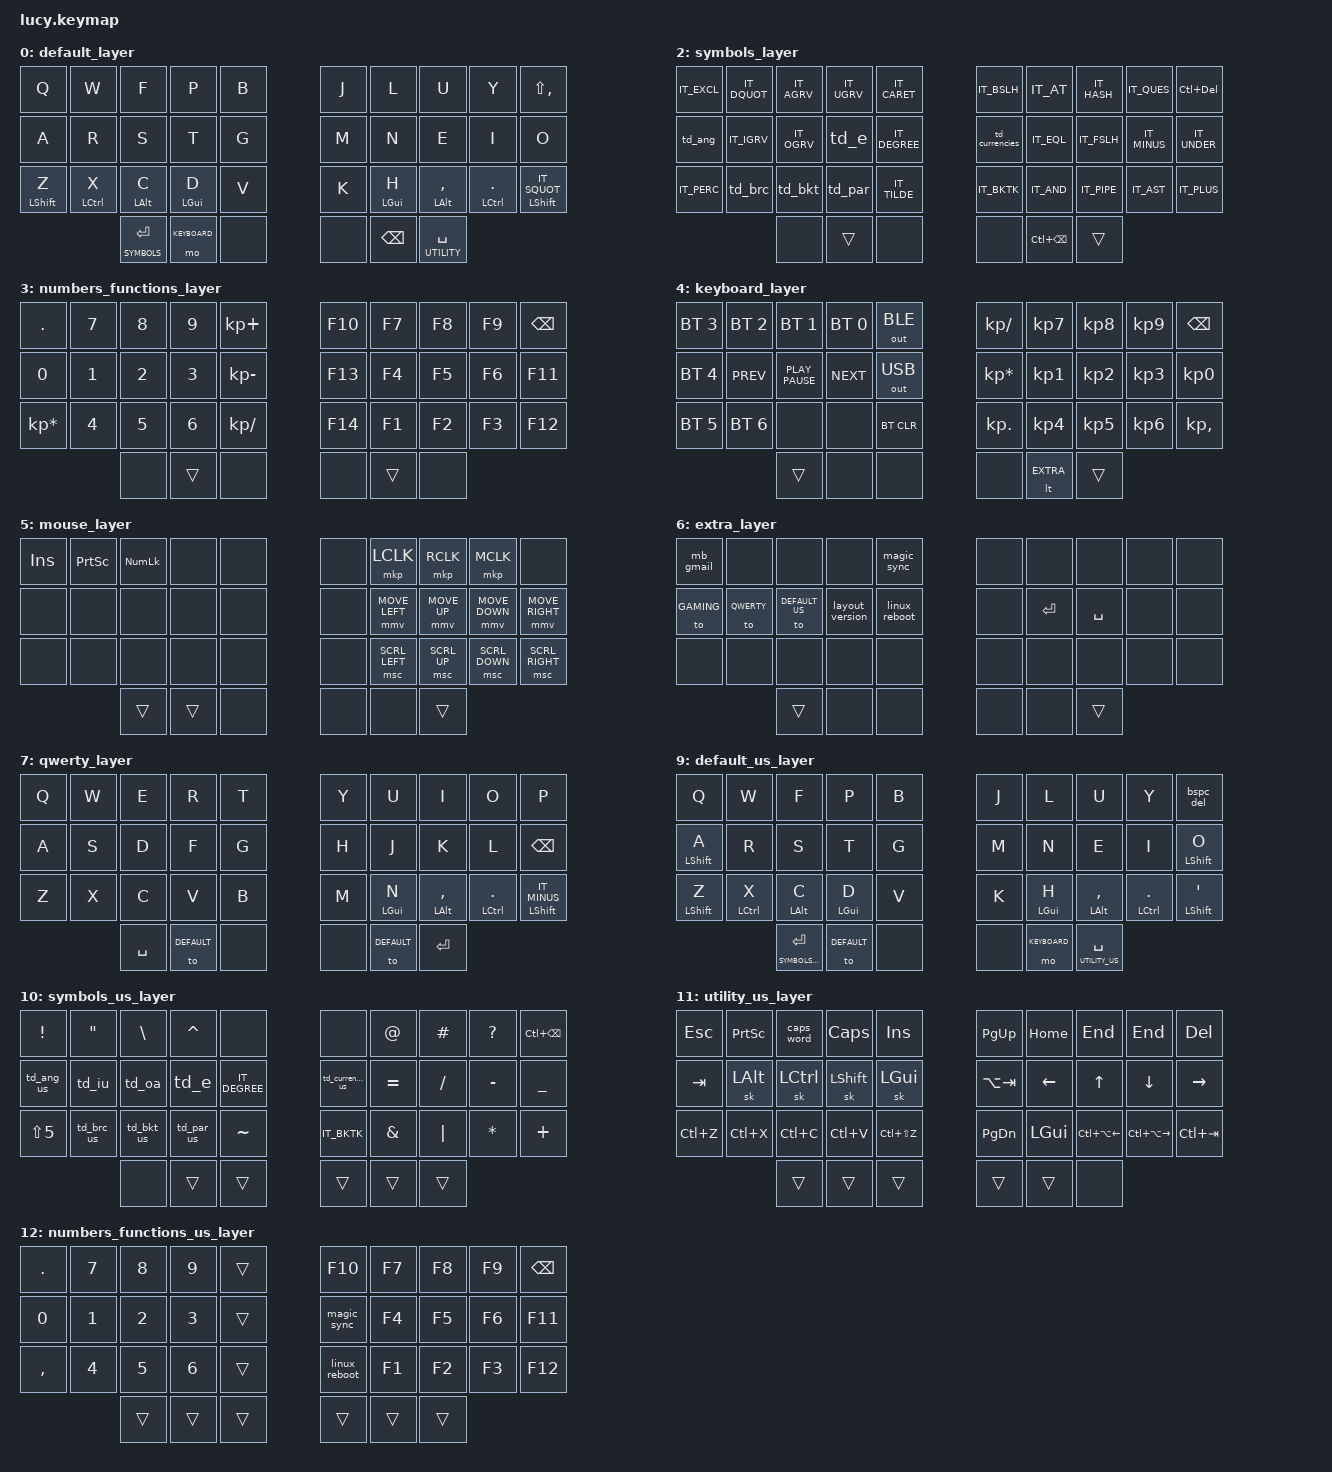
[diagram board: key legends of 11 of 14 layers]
/*
 * Copyright (c) 2020 The ZMK Contributors
 *
 * SPDX-License-Identifier: MIT
 */

/********************
 * Cotechino Layout *
 *                  *
 * Date: 2026-03-15 *
 * v1.1.0           *
 *                  *
 ********************/
// Versione del layout
#define LAYOUT_VERSION &kp N1 &kp DOT &kp N1 &kp DOT &kp N0

#include "./boards/shields/lucy/italian.keycodes"
#include "./emails.h"
#include "./secrets.h"

#include <behaviors.dtsi>
#include <dt-bindings/zmk/keys.h>
#include <dt-bindings/zmk/outputs.h>
#include <dt-bindings/zmk/bt.h>

// Mouse Emulation feature
#define ZMK_POINTING_DEFAULT_MOVE_VAL 700  // default: 600
#define ZMK_POINTING_DEFAULT_SCRL_VAL 10    // default: 10

#include <dt-bindings/zmk/pointing.h>

/***************************
*        LAYER CODES       *
****************************/

#define DEFAULT                 0

#define UTILITY                 1

#define SYMBOLS                 2

#define NUM_FUNC                3

#define KEYBOARD                4

#define MOUSE                   5

#define EXTRA                   6

#define QWERTY                  7

#define GAMING                  8
// ------------------------------
// I need a copy for every layer because I cannot activate lower number layers (can I?)

#define DEFAULT_US              9

#define SYMBOLS_US              10

#define UTILITY_US              11

#define NUM_FUNC_US             12

#define EXTRA_US                13

#define NONE_ROW &none &none &none &none &none

// Global mod-tap configuration
&mt {
    //tapping-term-ms = <300>;
    //quick_tap_ms = <0>;
    //flavor = "tap-preferred";
    //retro-tap;
};

// Caps Word configuration for italian
&caps_word {
    continue-list = <IT_UNDER IT_MINUS BACKSPACE>;
};

/ {

/********************************************************
*   MACROS
*********************************************************/

    macros {

    /**************************
    *      TYPING MACROS      *
    ***************************/

           mb_gmail: mb_gmail {
               compatible = "zmk,behavior-macro";
               #binding-cells = <0>;
               wait-ms = <20>;
               tap-ms = <10>;
               bindings
                   = <
                   MB92_GMAIL
                   >
                   ;
           };

           layout_version: curr_version {
                compatible = "zmk,behavior-macro";
                #binding-cells = <0>;
                wait-ms = <20>;
                tap-ms = <10>;
                bindings
                    = <
                    LAYOUT_VERSION
                    >
                    ;
           };

    /******************************
    *       GENERIC MACROS        *
    *******************************/

           magic_sync: magic_sysrq_sync {
                compatible = "zmk,behavior-macro";
                #binding-cells = <0>;
                wait-ms = <500>;
                tap-ms = <40>;
                bindings
                     = <&macro_press &kp LALT>
                     , <&macro_press &kp PRINTSCREEN>
                     , <&macro_tap &kp S>
                     , <&macro_release &kp LALT>
                     , <&macro_release &kp PRINTSCREEN>
                     ;
            };

           linux_reboot: linux_reboot {
                compatible = "zmk,behavior-macro";
                #binding-cells = <0>;
                wait-ms = <100>;
                tap-ms = <40>;
                bindings
                     = <&macro_press &kp LALT>
                     , <&macro_press &kp PRINTSCREEN>
                     , <&kp R>
                     , <&kp E>
                     , <&macro_wait_time 1000>
                     , <&kp I>
                     , <&kp S>
                     , <&macro_wait_time 500>
                     , <&kp U>
                     , <&macro_pause_for_release>
                     , <&kp B>
                     , <&macro_release &kp LALT>
                     , <&macro_release &kp PRINTSCREEN>
                     ;
           };

/********************************************************
*   COMBOS
*********************************************************/

    combos {
        compatible = "zmk,combos";

        // Get back to default layer by pressing both thumb keys
        combo_escape_qwerty {
            timeout-ms = <100>;
            layers= <QWERTY>;
            key-positions = <30 35>;
            bindings = <&to DEFAULT>;
        };

        // easier to hit
        combo_escape_qwerty2 {
            timeout-ms = <150>;
            layers= <QWERTY>;
            key-positions = <16 17 18 19>;
            bindings = <&to DEFAULT>;
        };

        // combo to tab in qwerty
        combo_tab_qwerty {
            timeout-ms = <75>;
            layers = <QWERTY>;
            key-positions = <10 11>;
            bindings = <&kp TAB>;
        };

   };

/********************************************************
*   CONDITIONAL LAYERS
*********************************************************/

    conditional_layers {
        compatible = "zmk,conditional-layers";
        numfn_layer {
            if-layers = <UTILITY SYMBOLS>;
            then-layer = <NUM_FUNC>;
        };

        mouse_layer {
            if-layers = <SYMBOLS KEYBOARD>;
            then-layer = <MOUSE>;
        };

        numfn_us_layer {
            if-layers = <UTILITY_US SYMBOLS_US>;
            then-layer = <NUM_FUNC_US>;
        };

    };

/********************************************************
*   BEHAVIORS
*********************************************************/

    behaviors {

        /***********************************************
        *   AUTOSHIFT
        ***********************************************/
        #define AS(keycode) &as LS(keycode) keycode     // Autoshift Macro

        as: auto_shift {
                    compatible = "zmk,behavior-hold-tap";
                    #binding-cells = <2>;
                    tapping-term-ms = <180>;
                    quick-tap-ms = <125>;
                    global-quick-tap;
                    flavor = "tap-preferred";
                    bindings = <&kp>, <&kp>;
        };

        /*************************************************/

        // Delete with backspace + shift
        bspc_del: backspace_delete {
                    compatible = "zmk,behavior-mod-morph";
                    #binding-cells = <0>;
                    bindings = <&kp BACKSPACE>, <&kp DELETE>;
                    mods = <(MOD_LSFT|MOD_RSFT)>;
                    keep-mods = <0>;
        };

        // Behaviors for home row layers toggle

        llt: left_layer_toggle {
            compatible = "zmk,behavior-hold-tap";
            #binding-cells = <2>;
            tapping-term-ms = <200>;    // 250
            quick-tap-ms = <80>;
            flavor = "tap-preferred";
            bindings = <&mo>, <&kp>;
            hold-trigger-key-positions = <5 6 7 8 9 15 16 17 18 19 25 26 27 28 29>;    // <---[[right-hand keys]]
        };

        rlt: right_layer_toggle {
            compatible = "zmk,behavior-hold-tap";
            #binding-cells = <2>;
            tapping-term-ms = <200>;    //250
            quick-tap-ms = <80>;
            flavor = "tap-preferred";
            bindings = <&mo>, <&kp>;
            hold-trigger-key-positions = <0 1 2 3 4 10 11 12 13 14 20 21 22 23 24>;    // <---[[left-hand keys]]

        };

        // Behaviors for mods in the bottom row

        lm: left_mods {
            compatible = "zmk,behavior-hold-tap";
            #binding-cells = <2>;
            //flavor = "tap-unless-interrupted";
            flavor = "tap-preferred";
            tapping-term-ms = <145>;    // last value: 150
            quick-tap-ms = <80>;        // 125
            bindings = <&kp>, <&kp>;
            hold-trigger-key-positions = <5 6 7 8 9 15 16 17 18 19 25 26 27 28 29>;    // <---[[right-hand keys]]
        };

        rm: right_mods {
            compatible = "zmk,behavior-hold-tap";
            #binding-cells = <2>;
            //flavor = "tap-unless-interrupted";
            flavor = "tap-preferred";
            tapping-term-ms = <145>;    // last value: 150
            quick-tap-ms = <80>;        // 125
            bindings = <&kp>, <&kp>;
            hold-trigger-key-positions = <0 1 2 3 4 10 11 12 13 14 20 21 22 23 24>;    // <---[[left-hand keys]]
       };

    // Layer on left thumb is for quick access to symbols used while typing so I need a shorter window for triggering
    // the hold behavior. This is possible as RETURN is not used in the middle of something. Balanced behavior is perfect here
        qlt: quick_layer_toggle {
            compatible = "zmk,behavior-hold-tap";
            #binding-cells = <2>;
            tapping-term-ms = <125>;
            quick-tap-ms = <0>;
            flavor = "balanced";
            bindings = <&mo>, <&kp>;
       };

       // Tap-Dances for accented letters

        td_e: tap_dance_e {
           compatible = "zmk,behavior-tap-dance";
            #binding-cells = <0>;
            tapping-term-ms = <200>;
            //bindings = <&kp E>, <&kp IT_EGRV>, <&kp IT_EACU>;
            bindings = <&kp IT_EGRV>, <&kp IT_EACU>;
        };

        td_oa: tap_dance_o_a {
           compatible = "zmk,behavior-tap-dance";
            #binding-cells = <0>;
            tapping-term-ms = <200>;
            bindings = <&kp IT_OGRV>, <&kp IT_AGRV>;
        };

        td_iu: tap_dance_i_u {
           compatible = "zmk,behavior-tap-dance";
            #binding-cells = <0>;
            tapping-term-ms = <200>;
            bindings = <&kp IT_IGRV>, <&kp IT_UGRV>;
        };

        td_par: tap_dance_parentheses {
           compatible = "zmk,behavior-tap-dance";
            #binding-cells = <0>;
            tapping-term-ms = <180>;
            //bindings = <&kp IT_LPAR>, <&macro_par>, <&kp IT_RPAR>;
            bindings = <&kp IT_LPAR>, <&kp IT_RPAR>;
        };

        td_par_us: tap_dance_parentheses_us {
           compatible = "zmk,behavior-tap-dance";
            #binding-cells = <0>;
            tapping-term-ms = <180>;
            //bindings = <&kp IT_LPAR>, <&macro_par>, <&kp IT_RPAR>;
            bindings = <&kp LPAR>, <&kp RPAR>;
        };

        td_bkt: tap_dance_brackets {
           compatible = "zmk,behavior-tap-dance";
            #binding-cells = <0>;
            tapping-term-ms = <180>;
            //bindings = <&kp IT_LBKT>, <&macro_bkt>, <&kp IT_RBKT>;
            bindings = <&kp IT_LBKT>, <&kp IT_RBKT>;
        };

        td_bkt_us: tap_dance_brackets_us {
           compatible = "zmk,behavior-tap-dance";
            #binding-cells = <0>;
            tapping-term-ms = <180>;
            //bindings = <&kp IT_LBKT>, <&macro_bkt>, <&kp IT_RBKT>;
            bindings = <&kp LBKT>, <&kp RBKT>;
        };

        td_brc: tap_dance_braces {
           compatible = "zmk,behavior-tap-dance";
            #binding-cells = <0>;
            tapping-term-ms = <180>;
            //bindings = <&kp IT_LBRC>, <&macro_brc>, <&kp IT_RBRC>;
            bindings = <&kp IT_LBRC>, <&kp IT_RBRC>;
        };

        td_brc_us: tap_dance_braces_us {
           compatible = "zmk,behavior-tap-dance";
            #binding-cells = <0>;
            tapping-term-ms = <180>;
            //bindings = <&kp IT_LBRC>, <&macro_brc>, <&kp IT_RBRC>;
            bindings = <&kp LBRC>, <&kp RBRC>;
        };

        td_ang: tap_dance_angulars_simplifed {
           compatible = "zmk,behavior-tap-dance";
           #binding-cells = <0>;
           tapping-term-ms = <200>;
           //bindings = <&kp IT_LESS>, <&macro_ang>, <&kp IT_GREAT>;
           bindings = <&kp IT_LESS>, <&kp IT_GREAT>;
        };

        td_ang_us: tap_dance_angulars_simplifed_us {
           compatible = "zmk,behavior-tap-dance";
           #binding-cells = <0>;
           tapping-term-ms = <200>;
           //bindings = <&kp IT_LESS>, <&macro_ang>, <&kp IT_GREAT>;
           bindings = <&kp LESS_THAN>, <&kp GREATER_THAN>;
        };

        td_currencies: tap_dance_currencies {
           compatible = "zmk,behavior-tap-dance";
           #binding-cells = <0>;
           tapping-term-ms = <200>;
           bindings = <&kp IT_USD>, <&kp IT_EUR>, <&kp IT_PND>, <&kp IT_YEN>;
        };

        td_currencies_us: tap_dance_currencies_us {
           compatible = "zmk,behavior-tap-dance";
           #binding-cells = <0>;
           tapping-term-ms = <200>;
           bindings = <&kp DOLLAR>, <&kp IT_EUR>, <&kp IT_PND>, <&kp IT_YEN>;
        };

    };


/********************************************************
*                       KEYMAP                          *
*********************************************************/
        keymap {
                compatible = "zmk,keymap";

/*********************************************
*       DEFAULT layer with COLEMAK-DH        *
**********************************************/
// 0
/**
 * SOSTITUIRE BACKSPACE NEL MIGNOLO CON ';'
 */
       		default_layer {
		bindings = <
		&kp Q               &kp W               &kp F               &kp P               &kp B           &kp J               &kp L               &kp U               &kp Y               &kp LS(COMMA)
		&kp A               &kp R               &kp S               &kp T               &kp G           &kp M               &kp N               &kp E               &kp I               &kp O
		&lm LSHIFT Z        &lm LCTRL X         &lm LALT C          &lm LGUI D          &kp V           &kp K               &rm LGUI H          &rm LALT COMMA      &rm LCTRL DOT       &rm LSHIFT IT_SQUOT
                                                &qlt SYMBOLS RET    &mo KEYBOARD        &none           &none               &kp BACKSPACE       &lt UTILITY SPACE
		>;
		};

/*********************************************
*               UTILITY LAYER                *
*********************************************/
// 1
		    utility_layer {
		bindings = <
		&kp ESC             &kp LS(RET)         &kp CAPS            &caps_word          &none           &kp PAGE_UP         &kp HOME            &kp END             &kp LC(SPACE)       &kp DEL
		&kp TAB             &sk LALT            &sk LCTRL           &sk LSHIFT          &sk LGUI        &kp LA(TAB)         &kp LEFT            &kp UP              &kp DOWN            &kp RIGHT
		&kp LC(Z)           &kp LC(X)           &kp LC(C)           &kp LC(V)           &kp LC(LS(Z))   &kp PAGE_DOWN       &kp LC(LS(TAB))     &kp LC(LA(LEFT))    &kp LC(LA(RIGHT))   &kp LC(TAB)
                                                &trans              &kp LS(RET)         &none           &none               &none
		>;
		};

/*********************************************
*                   SYMBOLS                  *
*********************************************/
// 2
           symbols_layer {
		bindings = <// TODO: inserire una funzione per il mignolo
		&kp IT_EXCL         &kp IT_DQUOT        &kp IT_AGRV         &kp IT_UGRV         &kp IT_CARET    &kp IT_BSLH         &kp IT_AT           &kp IT_HASH         &kp IT_QUES         &kp LC(DEL)
		&td_ang             &kp IT_IGRV         &kp IT_OGRV         &td_e               &kp IT_DEGREE   &td_currencies      &kp IT_EQL          &kp IT_FSLH         &kp IT_MINUS        &kp IT_UNDER
		&kp IT_PERC         &td_brc             &td_bkt             &td_par             &kp IT_TILDE    &kp IT_BKTK         &kp IT_AND          &kp IT_PIPE         &kp IT_AST          &kp IT_PLUS
                                                &none               &trans              &none           &none               &kp LC(BACKSPACE)   &trans
		>;
		};

/*********************************************
*              NUMBERS/FUNCTIONS             *
*********************************************/
// 3 <- 1+2
		    numbers_functions_layer {
		bindings = <
		&kp DOT             &kp N7              &kp N8              &kp N9              &kp KP_PLUS          &kp F10             &kp F7              &kp F8              &kp F9              &kp BSPC
        &kp N0              &kp N1              &kp N2              &kp N3              &kp KP_MINUS         &kp F13             &kp F4              &kp F5              &kp F6              &kp F11
        &kp KP_ASTERISK     &kp N4              &kp N5              &kp N6              &kp KP_SLASH         &kp F14             &kp F1              &kp F2              &kp F3              &kp F12
                                                &none               &trans              &none                &none               &trans              &none
		>;
		};

/*********************************************
*                  KEYBOARD                  *
*********************************************/
// 4
            keyboard_layer {
        bindings = <
        &bt BT_SEL 3        &bt BT_SEL 2        &bt BT_SEL 1        &bt BT_SEL 0        &out OUT_BLE    &kp KP_DIVIDE         &kp KP_N7           &kp KP_N8           &kp KP_N9           &kp BSPC
        &bt BT_SEL 4        &kp K_PREV          &kp K_PLAY_PAUSE    &kp K_NEXT          &out OUT_USB    &kp KP_MULTIPLY       &kp KP_N1           &kp KP_N2           &kp KP_N3           &kp KP_N0
        &bt BT_SEL 5        &bt BT_SEL 6        &none               &none               &bt BT_CLR      &kp KP_DOT            &kp KP_N4           &kp KP_N5           &kp KP_N6           &kp KP_COMMA
                                                &trans              &none               &none           &none                 &lt EXTRA           &trans
        >;
        };

/******************************************
*                 MOUSE                  *
*****************************************/
// 5
            mouse_layer {
		bindings = <
		&kp INSERT          &kp PRINTSCREEN     &kp KP_NUMLOCK      &none               &none                   &none               &mkp LCLK           &mkp RCLK           &mkp MCLK           &none
		&none               &none               &none               &none               &none                   &none               &mmv MOVE_LEFT      &mmv MOVE_UP        &mmv MOVE_DOWN      &mmv MOVE_RIGHT
		&none               &none               &none               &none               &none                   &none               &msc SCRL_LEFT      &msc SCRL_UP        &msc SCRL_DOWN      &msc SCRL_RIGHT
                                                        &trans              &trans              &none                   &none               &none               &trans
		>;
		};

/*********************************************
*                   EXTRA                    *
*********************************************/
// 6 <- 5+4
//
/********
 * TODO: use this layer for macros
 * - insert email
 * -
 *******/
            extra_layer {
        bindings = <
        &mb_gmail           &none               &none               &none               &magic_sync     &none                 &none               &none               &none               &none
        &to GAMING          &to QWERTY          &to DEFAULT_US      &layout_version     &linux_reboot   &none                 &kp RET             &kp SPC             &none               &none
        &none               &none               &none               &none               &none           &none                 &none               &none               &none               &none
                                                &trans              &none               &none           &none                 &none               &trans
        >;
        };

/*********************************************
*                   QWERTY                   *
*********************************************/

       		qwerty_layer {
		bindings = <
		&kp Q               &kp W               &kp E               &kp R               &kp T           &kp Y               &kp U               &kp I               &kp O               &kp P
		&kp A               &kp S               &kp D               &kp F               &kp G           &kp H               &kp J               &kp K               &kp L               &kp BSPC
		&kp Z               &kp X               &kp C               &kp V               &kp B           &kp M               &mt LGUI N          &mt LALT COMMA       &mt LCTRL DOT       &mt LSHFT IT_MINUS
                                                &kp SPACE           &to DEFAULT         &none           &none               &to DEFAULT         &kp RET
		>;
		};

/*********************************************
*   GAMING
*********************************************/

            gaming_layer {
        bindings = <
        &kp LCTRL                &kp U               &kp D               &kp F               &kp TAB         NONE_ROW
        &kp Q                    &kp W               &kp E               &kp R               &kp T           NONE_ROW
        &kp LSHIFT               &kp X               &kp C               &kp V               &kp B           NONE_ROW
                                                     &kp SPACE           &kp ESC             &none           &none               &to DEFAULT         &kp RET
        >;
        };


/*           	gaming_layer {
    	bindings = <
    	&kp TAB             &kp Q               &kp W               &kp E               &kp R           &kp T               &kp Y               &kp U               &kp I               &kp O
    	&kp LSHIFT          &kp A               &kp S               &kp D               &kp F           &kp G               &kp J               &kp K               &kp L               &kp P
    	&kp LCTRL           &kp Z               &kp X               &kp C               &kp V           &kp B               &kp M               &kp N               &none               &none
                                                &kp SPC             &kp ESC             &none           &none               &to DEFAULT         &kp RET
    	>;
    	};

            gaming_layer {
        bindings = <
        &kp Q               &kp W               &kp E               &kp R               &kp T           &kp T               &kp Y               &kp U               &kp I               &kp O
        &kp LSHIFT          &kp Z               &kp X               &kp C               &kp B           &kp G               &kp J               &kp K               &kp L               &kp P
        &kp LCTRL           &kp V               &kp G               &kp H               &kp N           &kp TAB             &kp M               &kp N               &none               &none
                                                &kp SPACE             &kp ESC             &none           &none               &to DEFAULT         &kp RET
        >;
        };
*/

//-----------------------------------------------------------------------------------------------------------------------------------------------------------------
//-----------------------------------------------------------------------------------------------------------------------------------------------------------------
//-----------------------------------------------------------------------------------------------------------------------------------------------------------------

/*********************************************
*   DEFAULT US LAYOUT
*********************************************/

            default_us_layer {
		bindings = <
		&kp Q               &kp W               &kp F               &kp P               &kp B           &kp J               &kp L               &kp U               &kp Y               &bspc_del
		&lm LSHIFT A        &kp R               &kp S               &kp T               &kp G           &kp M               &kp N               &kp E               &kp I               &lm LSHIFT O
		&lm LSHIFT Z        &lm LCTRL X         &lm LALT C          &lm LGUI D          &kp V           &kp K               &rm LGUI H          &rm LALT COMMA       &rm LCTRL DOT       &rm LSHIFT SINGLE_QUOTE
                                                &qlt SYMBOLS_US RET &to DEFAULT         &none           &none               &mo KEYBOARD        &lt UTILITY_US SPACE
		>;
		};

/*********************************************
*   SYMBOLS US LAYOUT
*********************************************/

           symbols_us_layer {
		bindings = <
		&kp EXCL            &kp DOUBLE_QUOTES   &kp BACKSLASH       &kp CARET           &none           &none               &kp AT              &kp HASH            &kp QUESTION        &kp LC(BSPC)
		&td_ang_us          &td_iu              &td_oa              &td_e               &kp IT_DEGREE   &td_currencies_us   &kp EQUAL           &kp SLASH           &kp MINUS           &kp UNDER
		&kp LS(N5)          &td_brc_us          &td_bkt_us          &td_par_us          &kp TILDE       &kp IT_BKTK         &kp AMPS            &kp PIPE            &kp ASTERISK        &kp PLUS
                                                &none               &trans              &trans          &trans              &trans              &trans
		>;
		};

/*********************************************
*   UTILITY US LAYER
*********************************************/

		    utility_us_layer {
		bindings = <
		&kp ESC             &kp PRINTSCREEN     &caps_word          &kp CAPS            &kp INSERT      &kp PAGE_UP         &kp HOME            &kp END             &kp END             &kp DEL
		&kp TAB             &sk LALT            &sk LCTRL           &sk LSHIFT          &sk LGUI        &kp LA(TAB)         &kp LEFT            &kp UP              &kp DOWN            &kp RIGHT
		&kp LC(Z)           &kp LC(X)           &kp LC(C)           &kp LC(V)           &kp LC(LS(Z))   &kp PAGE_DOWN       &kp LGUI            &kp LC(LA(LEFT))    &kp LC(LA(RIGHT))   &kp LC(TAB)
                                                &trans              &trans              &trans          &trans              &trans              &none
		>;
		};

/*********************************************
*   NUMBERS/SYMBOLS
*********************************************/

		    numbers_functions_us_layer {
		bindings = <
		&kp DOT             &kp N7              &kp N8              &kp N9             &trans          &kp F10             &kp F7              &kp F8              &kp F9              &kp BSPC
        &kp N0              &kp N1              &kp N2              &kp N3             &trans          &magic_sync         &kp F4              &kp F5              &kp F6              &kp F11
        &kp COMMA           &kp N4              &kp N5              &kp N6             &trans          &linux_reboot       &kp F1              &kp F2              &kp F3              &kp F12
                                                &trans              &trans             &trans          &trans              &trans              &trans
		>;
		};

/*********************************************
*   EXTRA US
*********************************************/

           	extra_us_layer {
    	bindings = <
    	NONE_ROW NONE_ROW
    	&none &none &kp LSHIFT &kp LCTRL &to DEFAULT NONE_ROW
    	NONE_ROW NONE_ROW
        &none             &none         &none           &none               &none               &none
    	>;
    	};

    };

};
